# STM32MP157 register map
File version: 1.6
CPU: CM4 r0p1, little endian, no MPU, FPU, 4 interrupt priority bits
Registers are 32-bit, read-write, reset 0x0 unless marked. A register's access mark holds for its fields unless they carry their own. Offsets are from the block's base; [hi:lo] are bit positions; {n}, {i} and the like mark numbered series.

## HDMI_CEC
Base 0x40016000
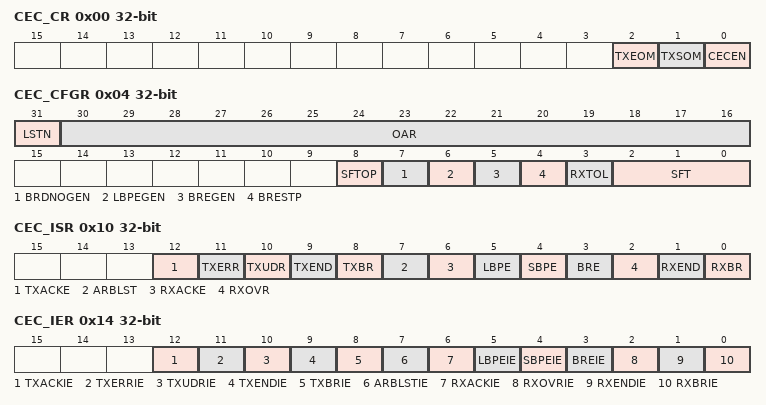
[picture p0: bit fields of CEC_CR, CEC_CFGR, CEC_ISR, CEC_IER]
0x00 CEC_CR — CEC control register
  [2] TXEOM, [1] TXSOM, [0] CECEN
0x04 CEC_CFGR — This register is used to configure the HDMI-CEC controller. It is mandatory to write CEC_CFGR only when CECEN=0.
  [31] LSTN, [30:16] OAR, [8] SFTOP, [7] BRDNOGEN, [6] LBPEGEN, [5] BREGEN, [4] BRESTP, [3] RXTOL, [2:0] SFT
0x08 CEC_TXDR — CEC Tx data register
  [7:0] TXD wo
0x0C CEC_RXDR ro — CEC Rx data register
  [7:0] RXD
0x10 CEC_ISR — CEC Interrupt and Status Register
  [12] TXACKE, [11] TXERR, [10] TXUDR, [9] TXEND, [8] TXBR, [7] ARBLST, [6] RXACKE, [5] LBPE, [4] SBPE, [3] BRE, [2] RXOVR, [1] RXEND, [0] RXBR
0x14 CEC_IER — CEC interrupt enable register
  [12] TXACKIE, [11] TXERRIE, [10] TXUDRIE, [9] TXENDIE, [8] TXBRIE, [7] ARBLSTIE, [6] RXACKIE, [5] LBPEIE, [4] SBPEIE, [3] BREIE, [2] RXOVRIE, [1] RXENDIE, [0] RXBRIE

## HDP
Base 0x5002A000
0x00 HDP_CTRL — HDP Control
  [0] EN
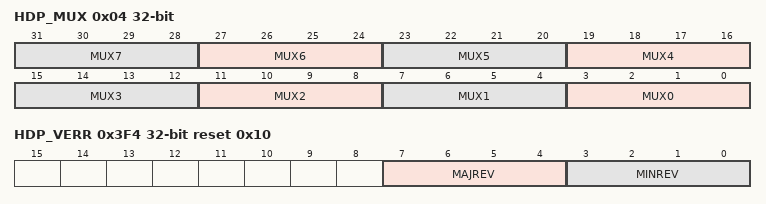
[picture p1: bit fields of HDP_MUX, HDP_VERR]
0x04 HDP_MUX — HDP multiplexing
  [4n+3:4n] MUX{n} (n=0..7)
0x10 HDP_VAL ro — HDP value
  [7:0] HDPVAL
0x14 HDP_GPOSET wo
  [7:0] HDPGPOSET
0x18 HDP_GPOCLR wo — HDP GPO clear
  [7:0] HDPGPOCLR
0x1C HDP_GPOVAL — HDP GPO value
  [7:0] HDPGPOVAL
0x3F4 HDP_VERR ro reset 0x10 — HDP version register
  [7:4] MAJREV, [3:0] MINREV
0x3F8 HDP_IPIDR ro reset 0x30002 — HDP IP identification register
  [31:0] ID
0x3FC HDP_SIDR ro reset 0xA3C5DD01 — HDP size identification register
  [31:0] SID

## HSEM
Base 0x4C000000
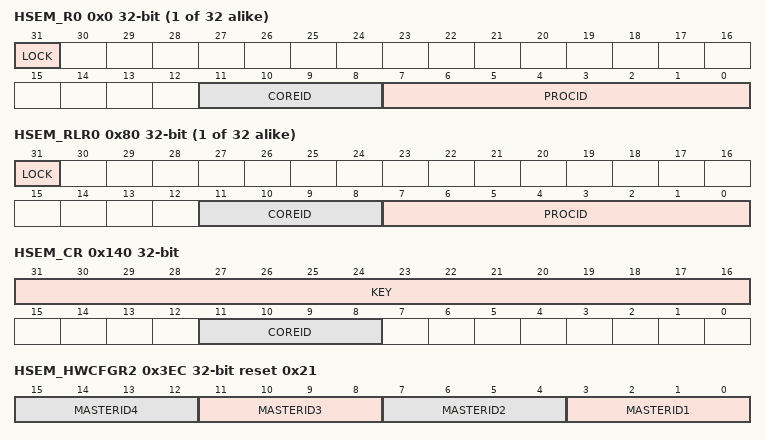
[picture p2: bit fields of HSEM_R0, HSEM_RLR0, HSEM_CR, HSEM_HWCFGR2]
{0x0+4i} HSEM_R{i} (i=0..31) — The HSEM_Rx shall be used to perform a 2-step Write lock and Read back. Only Write accesses with authorized AHB bus master IDs are granted. Write accesses with unauthorized AHB bus master IDs are discarded.
  [31] LOCK, [11:8] COREID, [7:0] PROCID
{0x80+4i} HSEM_RLR{i} ro (i=0..31) — Accesses the same physical bits as HSEM_Rx. The HSEM_RLRx shall be used to perform a 1-step Read lock. Only Read accesses with authorized AHB bus master IDs are granted. Read accesses with unauthorized AHB bus master IDs are discarded.
  [31] LOCK, [11:8] COREID, [7:0] PROCID
0x100 HSEM_C1IER — HSEM i1terrupt enable register
  [31:0] ISE
0x104 HSEM_C1ICR — HSEM i1terrupt clear register
  [31:0] ISC
0x108 HSEM_C1ISR ro — HSEM i1terrupt status register
  [31:0] ISF
0x10C HSEM_C1MISR ro — HSEM i1terrupt status register
  [31:0] MISF
0x110 HSEM_C2IER — HSEM i2terrupt enable register
  [31:0] ISE
0x114 HSEM_C2ICR — HSEM i2terrupt clear register
  [31:0] ISC
0x118 HSEM_C2ISR ro — HSEM i2terrupt status register
  [31:0] ISF
0x11C HSEM_C2MISR ro — HSEM i2terrupt status register
  [31:0] MISF
0x140 HSEM_CR wo — Only Write accesses with authorized AHB bus master IDs are granted. Write accesses with unauthorized AHB bus master IDs are discarded.
  [31:16] KEY, [11:8] COREID
0x144 HSEM_KEYR — HSEM interrupt clear register
  [31:16] KEY
0x3EC HSEM_HWCFGR2 ro reset 0x21 — HSEM hardware configuration register 2
  [4n-1:4n-4] MASTERID{n} (n=1..4)
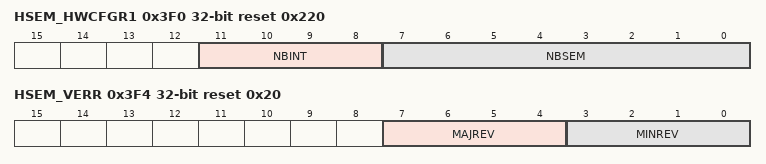
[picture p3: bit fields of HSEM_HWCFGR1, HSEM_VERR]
0x3F0 HSEM_HWCFGR1 ro reset 0x220 — HSEM hardware configuration register 1
  [11:8] NBINT, [7:0] NBSEM
0x3F4 HSEM_VERR ro reset 0x20 — HSEM IP version register
  [7:4] MAJREV, [3:0] MINREV
0x3F8 HSEM_IPIDR ro reset 0x100072 — HSEM IP identification register
  [31:0] IPID
0x3FC HSEM_SIDR ro reset 0xA3C5DD01 — HSEM size identification register
  [31:0] SID

## I2C1
Base 0x40012000
Same registers: I2C2 0x40013000, I2C3 0x40014000, I2C5 0x40015000, I2C4 0x5C002000, I2C6 0x5C009000
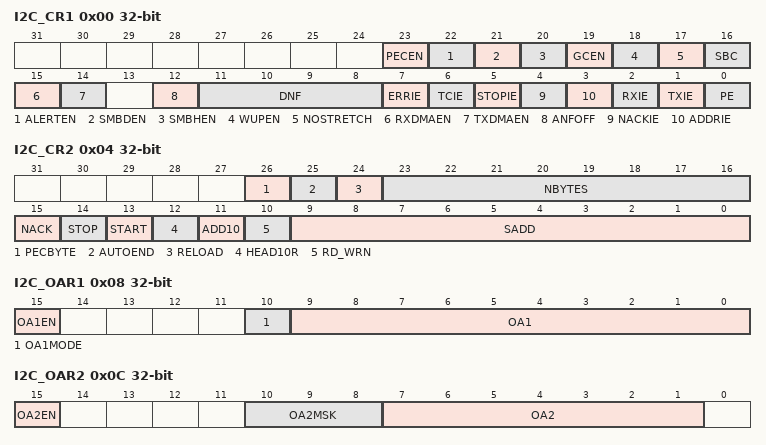
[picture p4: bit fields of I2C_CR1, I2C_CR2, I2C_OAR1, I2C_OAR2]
0x00 I2C_CR1 — Access: No wait states, except if a write access occurs while a write access to this register is ongoing. In this case, wait states are inserted in the second write access until the previous one is completed. The latency of the second write access can be up to 2xi2c_pclk+6xi2c_ker_ck.
  [23] PECEN, [22] ALERTEN, [21] SMBDEN, [20] SMBHEN, [19] GCEN, [18] WUPEN, [17] NOSTRETCH, [16] SBC, [15] RXDMAEN, [14] TXDMAEN, [12] ANFOFF, [11:8] DNF, [7] ERRIE, [6] TCIE, [5] STOPIE, [4] NACKIE, [3] ADDRIE, [2] RXIE, [1] TXIE, [0] PE
0x04 I2C_CR2 — Access: No wait states, except if a write access occurs while a write access to this register is ongoing. In this case, wait states are inserted in the second write access until the previous one is completed. The latency of the second write access can be up to 2 x i2c_pclk + 6 x i2c_ker_ck.
  [26] PECBYTE, [25] AUTOEND, [24] RELOAD, [23:16] NBYTES, [15] NACK, [14] STOP, [13] START, [12] HEAD10R, [11] ADD10, [10] RD_WRN, [9:0] SADD
0x08 I2C_OAR1 — Access: No wait states, except if a write access occurs while a write access to this register is ongoing. In this case, wait states are inserted in the second write access until the previous one is completed. The latency of the second write access can be up to 2 x i2c_pclk + 6 x i2c_ker_ck.
  [15] OA1EN, [10] OA1MODE, [9:0] OA1
0x0C I2C_OAR2 — Access: No wait states, except if a write access occurs while a write access to this register is ongoing. In this case, wait states are inserted in the second write access until the previous one is completed. The latency of the second write access can be up to 2 x i2c_pclk + 6 x i2c_ker_ck.
  [15] OA2EN, [10:8] OA2MSK, [7:1] OA2
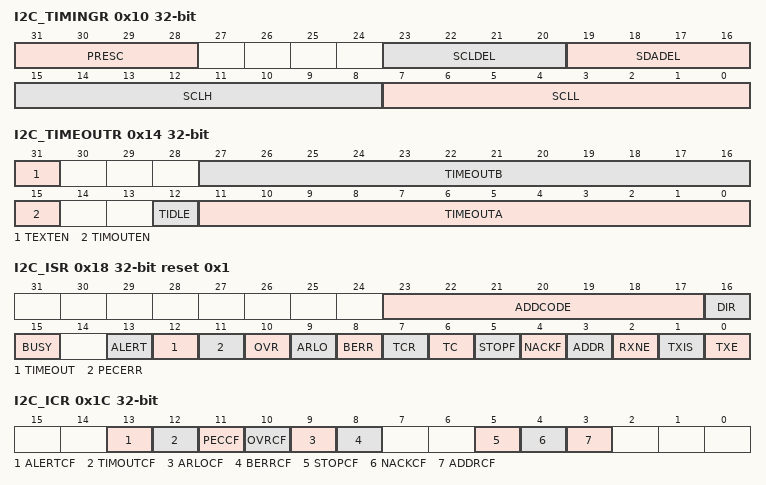
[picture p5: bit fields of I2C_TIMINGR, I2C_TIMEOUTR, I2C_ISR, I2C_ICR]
0x10 I2C_TIMINGR — Access: No wait states
  [31:28] PRESC, [23:20] SCLDEL, [19:16] SDADEL, [15:8] SCLH, [7:0] SCLL
0x14 I2C_TIMEOUTR — Access: No wait states, except if a write access occurs while a write access to this register is ongoing. In this case, wait states are inserted in the second write access until the previous one is completed. The latency of the second write access can be up to 2 x i2c_pclk + 6 x i2c_ker_ck.
  [31] TEXTEN, [27:16] TIMEOUTB, [15] TIMOUTEN, [12] TIDLE, [11:0] TIMEOUTA
0x18 I2C_ISR access per field reset 0x1 — Access: No wait states
  [23:17] ADDCODE ro, [16] DIR ro, [15] BUSY ro, [13] ALERT ro, [12] TIMEOUT ro, [11] PECERR ro, [10] OVR ro, [9] ARLO ro, [8] BERR ro, [7] TCR ro, [6] TC ro, [5] STOPF ro, [4] NACKF ro, [3] ADDR ro, [2] RXNE ro, [1] TXIS rw, [0] TXE rw
0x1C I2C_ICR wo — Access: No wait states
  [13] ALERTCF, [12] TIMOUTCF, [11] PECCF, [10] OVRCF, [9] ARLOCF, [8] BERRCF, [5] STOPCF, [4] NACKCF, [3] ADDRCF
0x20 I2C_PECR ro — Access: No wait states
  [7:0] PEC
0x24 I2C_RXDR ro — Access: No wait states
  [7:0] RXDATA
0x28 I2C_TXDR — Access: No wait states
  [7:0] TXDATA
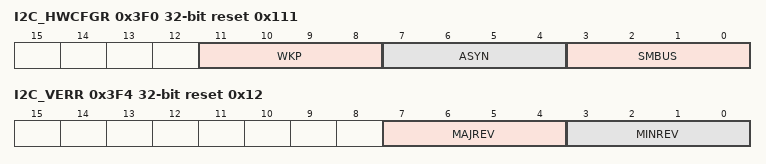
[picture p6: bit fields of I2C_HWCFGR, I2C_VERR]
0x3F0 I2C_HWCFGR ro reset 0x111 — I2C hardware configuration register
  [11:8] WKP, [7:4] ASYN, [3:0] SMBUS
0x3F4 I2C_VERR ro reset 0x12 — I2C version register
  [7:4] MAJREV, [3:0] MINREV
0x3F8 I2C_IPIDR ro reset 0x130012 — I2C identification register
  [31:0] ID
0x3FC I2C_SIDR ro reset 0xA3C5DD01 — I2C size identification register
  [31:0] SID
